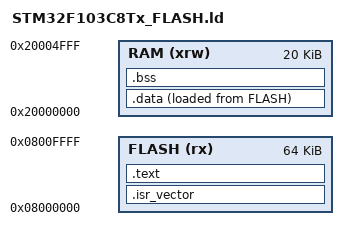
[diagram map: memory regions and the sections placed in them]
ENTRY(Reset_Handler)

_estack = ORIGIN(RAM) + LENGTH(RAM);

MEMORY
{
  FLASH (rx)  : ORIGIN = 0x08000000, LENGTH = 64K
  RAM   (xrw) : ORIGIN = 0x20000000, LENGTH = 20K
}

SECTIONS
{
  .isr_vector :
  {
    . = ALIGN(4);
    KEEP(*(.isr_vector))
    . = ALIGN(4);
  } >FLASH

  .text :
  {
    . = ALIGN(4);
    *(.text)
    *(.text*)
    *(.rodata)
    *(.rodata*)
    . = ALIGN(4);
    _etext = .;
  } >FLASH

  _sidata = LOADADDR(.data);

  .data :
  {
    . = ALIGN(4);
    _sdata = .;
    *(.data)
    *(.data*)
    . = ALIGN(4);
    _edata = .;
  } >RAM AT> FLASH

  .bss :
  {
    . = ALIGN(4);
    _sbss = .;
    *(.bss)
    *(.bss*)
    *(COMMON)
    . = ALIGN(4);
    _ebss = .;
  } >RAM

  PROVIDE(end = _ebss);
  PROVIDE(_end = _ebss);
  PROVIDE(__end__ = _ebss);

  .ARM.attributes 0 : { *(.ARM.attributes) }
}
